# STM32H503 register map
File version: 0.3
CPU: CM33 r0p0, little endian, MPU, FPU, 4 interrupt priority bits
Registers are 32-bit, read-write, reset 0x0 unless marked. A register's access mark holds for its fields unless they carry their own. Offsets are from the block's base; [hi:lo] are bit positions.

## RCC — Reset and clock controller
Base 0x44020C00
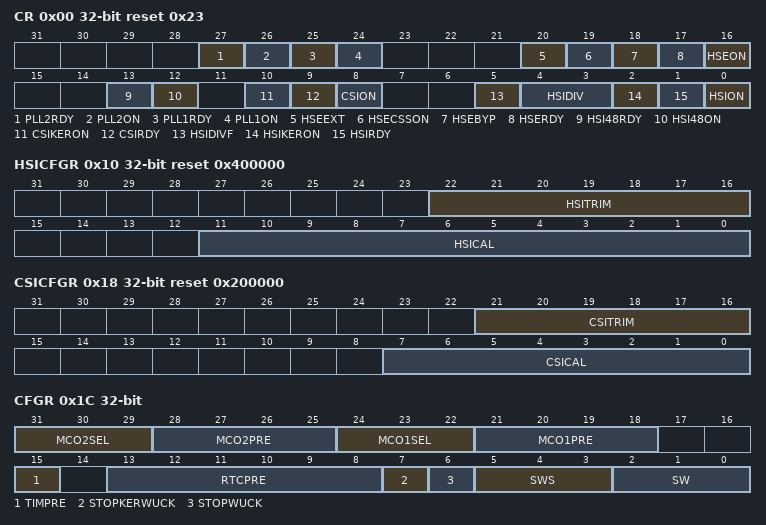
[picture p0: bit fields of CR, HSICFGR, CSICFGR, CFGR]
0x00 CR access per field reset 0x23 — RCC clock control register
  [27] PLL2RDY ro — PLL2 clock ready flag Set by hardware to indicate that the PLL is locked.
  [26] PLL2ON rw — PLL2 enable Set and cleared by software to enable PLL2. Cleared by hardware when entering Stop or Standby mode.
  [25] PLL1RDY ro — PLL1 clock ready flag Set by hardware to indicate that the PLL1 is locked.
  [24] PLL1ON rw — PLL1 enable Set and cleared by software to enable PLL1. Cleared by hardware when entering Stop or Standby mode. Note that the hardware prevents writing this bit to 0, if the PLL1 output is used as the system clock.
  [20] HSEEXT rw — external high speed clock type in Bypass mode Set and reset by software to select the external clock type (analog or digital). The external clock must be enabled with the HSEON bit to be used by the device. The HSEEXT bit can be written only if the HSE oscillator is disabled.
  [19] HSECSSON rw — HSE clock security system enable Set by software to enable clock security system on HSE. This bit is “set only” (disabled by a system reset or when the system enters in Standby mode). When HSECSSON is set, the clock detector is enabled by hardware when the HSE is ready and disabled by hardware if an oscillator failure is detected.
  [18] HSEBYP rw — HSE clock bypass Set and cleared by software to bypass the oscillator with an external clock. The external clock must be enabled with the HSEON bit to be used by the device. The HSEBYP bit can be written only if the HSE oscillator is disabled.
  [17] HSERDY ro — HSE clock ready flag Set by hardware to indicate that the HSE oscillator is stable.
  [16] HSEON rw — HSE clock enable Set and cleared by software. Cleared by hardware to stop the HSE when entering Stop or Standby mode. This bit cannot be cleared if the HSE is used directly (via SW mux) as system clock, or if the HSE is selected as reference clock for PLL1 with PLL1 enabled (PLL1ON bit set to 1).
  [13] HSI48RDY ro — HSI48 clock ready flag Set by hardware to indicate that the HSI48 oscillator is stable.
  [12] HSI48ON rw — HSI48 clock enable Set by software and cleared by software or by the hardware when the system enters to Stop or Standby mode.
  [10] CSIKERON rw — CSI clock enable in Stop mode Set and reset by software to force the CSI to ON, even in Stop mode, in order to be quickly available as kernel clock for some peripherals. This bit has no effect on the value of CSION.
  [9] CSIRDY ro — CSI clock ready flag Set by hardware to indicate that the CSI oscillator is stable. This bit is activated only if the RC is enabled by CSION (it is not activated if the CSI is enabled by CSIKERON or by a peripheral request).
  [8] CSION rw — CSI clock enable Set and reset by software to enable/disable CSI clock for system and/or peripheral. Set by hardware to force the CSI to ON when the system leaves Stop mode, if STOPWUCK = 1 or STOPKERWUCK = 1. This bit cannot be cleared if the CSI is used directly (via SW mux) as system clock, or if the CSI is selected as reference clock for PLL1 with PLL1 enabled (PLL1ON bit set to 1).
  [5] HSIDIVF ro — HSI divider flag Set and reset by hardware. As a write operation to HSIDIV has not an immediate effect on the frequency, this flag indicates the current status of the HSI divider. HSIDIVF goes immediately to 0 when HSIDIV value is changed, and is set back to 1 when the output frequency matches the value programmed into HSIDIV.
  [4:3] HSIDIV rw — HSI clock divider Set and reset by software. These bits allow selecting a division ratio in order to configure the wanted HSI clock frequency. The HSIDIV cannot be changed if the HSI is selected as reference clock for at least one enabled PLL (PLLxON bit set to 1). In that case, the new HSIDIV value is ignored.
  [2] HSIKERON rw — HSI clock enable in Stop mode Set and reset by software to force the HSI to ON, even in Stop mode, in order to be quickly available as kernel clock for peripherals. This bit has no effect on the value of HSION.
  [1] HSIRDY ro — HSI clock ready flag Set by hardware to indicate that the HSI oscillator is stable.
  [0] HSION rw — HSI clock enable Set and cleared by software. Set by hardware to force the HSI to ON when the product leaves Stop mode, if STOPWUCK = 1 or STOPKERWUCK = 1. Set by hardware to force the HSI to ON when the product leaves Standby mode or in case of a failure of the HSE which is used as the system clock source. This bit cannot be cleared if the HSI is used directly (via SW mux) as system clock, or if the HSI is selected as reference clock for PLL1 with PLL1 enabled (PLL1ON bit set to 1).
0x10 HSICFGR access per field reset 0x400000 (reset mask 0xFFFFF000) — RCC HSI calibration register
  [22:16] HSITRIM rw — HSI clock trimming Set by software to adjust calibration. HSITRIM field is added to the engineering option bytes loaded during reset phase (FLASH_HSI_OPT) in order to form the calibration trimming value. HSICAL = HSITRIM + FLASH_HSI_OPT. After a change of HSITRIM it takes one system clock cycle before the new HSITRIM value is updated Note: The reset value of the field is 0x40.
  [11:0] HSICAL ro — HSI clock calibration Set by hardware by option byte loading during system reset nreset. Adjusted by software through trimming bits HSITRIM. This field represents the sum of engineering option byte calibration value and HSITRIM bits value.
0x14 CRRCR ro (reset mask 0xFFFFF000) — RCC clock recovery RC register
  [9:0] HSI48CAL — Internal RC 48 MHz clock calibration Set by hardware by option-byte loading during system reset NRESET. Read-only.
0x18 CSICFGR reset 0x200000 (reset mask 0xFFFFF000) — RCC CSI calibration register
  [21:16] CSITRIM — CSI clock trimming Set by software to adjust calibration. CSITRIM field is added to the engineering option bytes loaded during reset phase (FLASH_CSI_OPT) in order to form the calibration trimming value. CSICAL = CSITRIM + FLASH_CSI_OPT. Note: The reset value of the field is 0x20.
  [7:0] CSICAL — CSI clock calibration Set by hardware by option byte loading during system reset NRESET. Adjusted by software through trimming bits CSITRIM. This field represents the sum of engineering option byte calibration value and CSITRIM bits value.
0x1C CFGR access per field — RCC clock configuration register
  [31:29] MCO2SEL rw — microcontroller clock output 2 Set and cleared by software. Clock source selection may generate glitches on MCO2. It is highly recommended to configure these bits only after reset, before enabling the external oscillators and the PLLs. others: reserved
  [28:25] MCO2PRE rw — MCO2 prescaler Set and cleared by software to configure the prescaler of the MCO2. Modification of this prescaler may generate glitches on MCO2. It is highly recommended to change this prescaler only after reset, before enabling the external oscillators and the PLLs. ...
  [24:22] MCO1SEL rw — Microcontroller clock output 1 Set and cleared by software. Clock source selection may generate glitches on MCO1. It is highly recommended to configure these bits only after reset, before enabling the external oscillators and the PLLs. others: reserved
  [21:18] MCO1PRE rw — MCO1 prescaler Set and cleared by software to configure the prescaler of the MCO1. Modification of this prescaler may generate glitches on MCO1. It is highly recommended to change this prescaler only after reset, before enabling the external oscillators and the PLLs. ...
  [15] TIMPRE rw — timers clocks prescaler selection This bit is set and reset by software to control the clock frequency of all the timers connected to APB1 and APB2 domains.
  [13:8] RTCPRE rw — HSE division factor for RTC clock Set and cleared by software to divide the HSE to generate a clock for RTC. Caution: The software must set these bits correctly to ensure that the clock supplied to the RTC is lower than 1 MHz. These bits must be configured if needed before selecting the RTC clock source. ...
  [7] STOPKERWUCK rw — kernel clock selection after a wakeup from system Stop Set and reset by software to select the kernel wakeup clock from system Stop.
  [6] STOPWUCK rw — system clock selection after a wakeup from system Stop Set and reset by software to select the system wakeup clock from system Stop. The selected clock is also used as emergency clock for the clock security system (CSS) on HSE. 0: HSI selected as wakeup clock from system Stop (default after reset) STOPWUCK must not be modified when CSS is enabled (by HSECSSON bit) and the system clock is HSE (SWS = 10) or a switch on HSE is requested (SW =10).
  [5:3] SWS ro — system clock switch status Set and reset by hardware to indicate which clock source is used as system clock. 000: HSI used as system clock (hsi_ck) (default after reset). others: reserved
  [2:0] SW rw — system clock and trace clock switch Set and reset by software to select system clock and trace clock sources (sys_ck). Set by hardware in order to: - force the selection of the HSI or CSI (depending on STOPWUCK selection) when leaving a system Stop mode - force the selection of the HSI in case of failure of the HSE when used directly or indirectly as system clock others: reserved
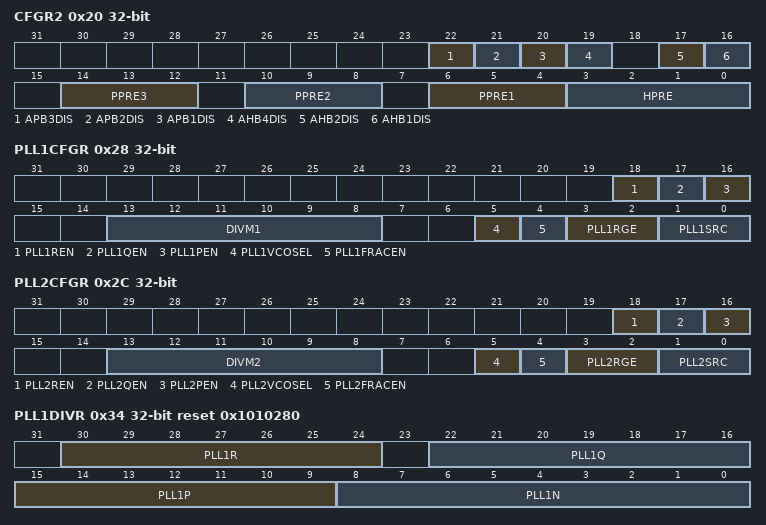
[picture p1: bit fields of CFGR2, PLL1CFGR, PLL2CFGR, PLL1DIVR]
0x20 CFGR2 — RCC CPU domain clock configuration register 2
  [22] APB3DIS — APB3 clock disable value.Set and cleared by software This bit can be set in order to further reduce power consumption, when none of the APB3 peripherals are used and when their clocks are disabled in RCC_APB3ENR. When this bit is set, all the APB3 peripherals clocks are off. control bits
  [21] APB2DIS — APB2 clock disable value This bit can be set in order to further reduce power consumption, when none of the APB2 peripherals are used and when their clocks are disabled in RCC_APB2ENR. When this bit is set, all the APB2 peripherals clocks are off. control bits
  [20] APB1DIS — APB1 clock disable value This bit can be set in order to further reduce power consumption, when none of the APB1 peripherals (except IWDG) are used and when their clocks are disabled in RCC_APB1ENR. When this bit is set, all the APB1 peripherals clocks are off, except for IWDG. control bits
  [19] AHB4DIS — AHB4 clock disable This bit can be set in order to further reduce power consumption, when none of the AHB4 peripherals from RCC_AHB4ENR are used and when their clocks are disabled in RCC_AHB4ENR. When this bit is set, all the AHB4 peripherals clocks from RCC_AHB4ENR are off. enable control bits
  [17] AHB2DIS — AHB2 clock disable This bit can be set in order to further reduce power consumption, when none of the AHB2 peripherals from RCC_AHB2ENR are used and when their clocks are disabled in RCC_AHB2ENR. When this bit is set, all the AHB2 peripherals clocks from RCC_AHB2ENR are off. enable control bits
  [16] AHB1DIS — AHB1 clock disable This bit can be set in order to further reduce power consumption, when none of the AHB1 peripherals from RCC_AHB1ENR are used and when their clocks are disabled in RCC_AHB1ENR. When this bit is set, all the AHB1 peripherals clocks from RCC_AHB1ENR are off. enable control bits
  [14:12] PPRE3 — APB low-speed prescaler (APB3) Set and reset by software to control APB low-speed clocks division factor. The clocks are divided with the new prescaler factor from 1 to 16 APB cycles after PPRE3 write. 0xx: rcc_pclk3 = rcc_hclk1
  [10:8] PPRE2 — APB high-speed prescaler (APB2) Set and reset by software to control APB high-speed clocks division factor. The clocks are divided with the new prescaler factor from 1 to 16 APB cycles after PPRE2 write. 0xx: rcc_pclk2 = rcc_hclk1
  [6:4] PPRE1 — APB low-speed prescaler (APB1) Set and reset by software to control the division factor of rcc_pclk1. The clock is divided by the new prescaler factor from 1 to 16 cycles of rcc_hclk after PPRE write. 0xx: rcc_pclk1 = rcc_hclk1 (default after reset)
  [3:0] HPRE — AHB prescaler Set and reset by software to control the division factor of rcc_hclk. Changing this division ratio has an impact on the frequency of all bus matrix clocks 0xxx: rcc_hclk = sys_ck (default after reset)
0x28 PLL1CFGR — RCC PLL clock source selection register
  [18] PLL1REN — PLL1 DIVR divider output enable Set and reset by software to enable the pll1_r_ck output of the PLL1. To save power, DIVR1EN and DIVR1 bits must be set to 0 when the pll1_r_ck is not used. This bit can be written only when the PLL1 is disabled (PLL1ON = 0 and PLL1RDY = 0).
  [17] PLL1QEN — PLL1 DIVQ divider output enable Set and reset by software to enable the pll1_q_ck output of the PLL1. In order to save power, when the pll1_q_ck output of the PLL1 is not used, the pll1_q_ck must be disabled. This bit can be written only when the PLL1 is disabled (PLL1ON = 0 and PLL1RDY = 0).
  [16] PLL1PEN — PLL1 DIVP divider output enable Set and reset by software to enable the pll1_p_ck output of the PLL1. This bit can be written only when the PLL1 is disabled (PLL1ON = 0 and PLL1RDY = 0). In order to save power, when the pll1_p_ck output of the PLL1 is not used, the pll1_p_ck must be disabled.
  [13:8] DIVM1 — prescaler for PLL1 Set and cleared by software to configure the prescaler of the PLL1. The hardware does not allow any modification of this prescaler when PLL1 is enabled (PLL1ON = 1 or PLL1RDY = 1). In order to save power when PLL1 is not used, the value of DIVM1 must be set to 0. ... ...
  [5] PLL1VCOSEL — PLL1 VCO selection Set and reset by software to select the proper VCO frequency range used for PLL1. This bit must be written before enabling the PLL1.
  [4] PLL1FRACEN — PLL1 fractional latch enable Set and reset by software to latch the content of FRACN1 into the sigma-delta modulator. In order to latch the FRACN1 value into the sigma-delta modulator, PLL1FRACEN must be set to 0, then set to 1. The transition 0 to 1 transfers the content of FRACN1 into the modulator.
  [3:2] PLL1RGE — PLL1 input frequency range Set and reset by software to select the proper reference frequency range used for PLL1. This bit must be written before enabling the PLL1.
  [1:0] PLL1SRC — DIVMx and PLLs clock source selection Set and reset by software to select the PLL clock source. These bits can be written only when all PLLs are disabled. In order to save power, when no PLL is used, the value of PLL1SRC must be set to '00'. 00: no clock send to DIVMx divider and PLLs (default after reset).
0x2C PLL2CFGR — RCC PLL clock source selection register
  [18] PLL2REN — PLL2 DIVR divider output enable Set and reset by software to enable the pll2_r_ck output of the PLL2. To save power, DIVR2EN and DIVR2 bits must be set to 0 when the pll2_r_ck is not used.
  [17] PLL2QEN — PLL2 DIVQ divider output enable Set and reset by software to enable the pll2_q_ck output of the PLL2. To save power, when the pll2_q_ck output of the PLL2 is not used, the pll2_q_ck must be disabled.
  [16] PLL2PEN — PLL2 DIVP divider output enable Set and reset by software to enable the pll2_p_ck output of the PLL2. To save power, when the pll2_p_ck output of the PLL2 is not used, the pll2_p_ck must be disabled.
  [13:8] DIVM2 — prescaler for PLL2 Set and cleared by software to configure the prescaler of the PLL2. The hardware does not allow any modification of this prescaler when PLL2 is enabled (PLL2ON = 1 or PLL2RDY = 1). In order to save power when PLL2 is not used, the value of DIVM2 must be set to 0. ... ...
  [5] PLL2VCOSEL — PLL2 VCO selection Set and reset by software to select the proper VCO frequency range used for PLL2. This bit must be written before enabling the PLL2.
  [4] PLL2FRACEN — PLL2 fractional latch enable Set and reset by software to enable the pll2_p_ck output of the PLL2. To save power, when the pll2_p_ck output of the PLL2 is not used, the pll2_p_ck must be disabled.
  [3:2] PLL2RGE — PLL2 input frequency range Set and reset by software to select the proper reference frequency range used for PLL2. These bits must be written before enabling the PLL2.
  [1:0] PLL2SRC — DIVMx and PLLs clock source selection Set and reset by software to select the PLL clock source. These bits can be written only when all PLLs are disabled. In order to save power, when no PLL is used, the value of PLL2SRC must be set to '00'.
0x34 PLL1DIVR reset 0x1010280 — RCC PLL1 dividers register
  [30:24] PLL1R — PLL1 DIVR division factor Set and reset by software to control the frequency of the pll1_r_ck clock. These bits can be written only when the PLL1 is disabled (PLL1ON = 0 and PLL1RDY = 0). ...
  [22:16] PLL1Q — PLL1 DIVQ division factor Set and reset by software to control the frequency of the pll1_q_ck clock. These bits can be written only when the PLL1 is disabled (PLL1ON = 0 and PLL1RDY = 0). ...
  [15:9] PLL1P — PLL1 DIVP division factor Set and reset by software to control the frequency of the pll1_p_ck clock. These bits can be written only when the PLL1 is disabled (PLL1ON = 0 and PLL1RDY = 0). Note that odd division factors are not allowed. ...
  [8:0] PLL1N — Multiplication factor for PLL1VCO Set and reset by software to control the multiplication factor of the VCO. These bits can be written only when the PLL is disabled (PLL1ON = 0 and PLL1RDY = 0). ... ... Others: reserved
0x38 PLL1FRACR — RCC PLL1 fractional divider register
  [15:3] PLL1FRACN — fractional part of the multiplication factor for PLL1 VCO Set and reset by software to control the fractional part of the multiplication factor of the VCO. These bits can be written at any time, allowing dynamic fine-tuning of the PLL1 VCO. The software must set correctly these bits to insure that the VCO output frequency is between its valid frequency range, that is: * 128 to 560 MHz if PLL1VCOSEL = 0 * 150 to 420 MHz if PLL1VCOSEL = 1 VCO output frequency = Fref1_ck x (PLL1N + (PLL1FRACN / 213)), with * PLL1N between 8 and 420 * PLL1FRACN can be between 0 and 213- 1 * The input frequency Fref1_ck must be between 1 and 16 MHz. To change the PLL1FRACN value on-the-fly even if the PLL is enabled, the application must proceed as follows: * Set the bit PLL1FRACEN to 0 * Write the new fractional value into PLL1FRACN * Set the bit PLL1FRACEN to 1
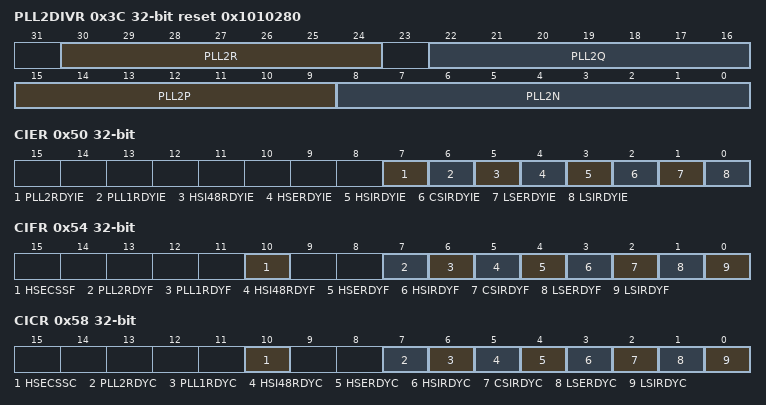
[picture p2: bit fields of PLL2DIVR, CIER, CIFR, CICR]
0x3C PLL2DIVR reset 0x1010280 — RCC PLL1 dividers register
  [30:24] PLL2R — PLL2 DIVR division factor Set and reset by software to control the frequency of the pll2_r_ck clock. These bits can be written only when the PLL1 is disabled (PLL2ON = 0 and PLL2RDY = 0). ...
  [22:16] PLL2Q — PLL2 DIVQ division factor Set and reset by software to control the frequency of the pll2_q_ck clock. These bits can be written only when the PLL2 is disabled (PLL2ON = 0 and PLL2RDY = 0). ...
  [15:9] PLL2P — PLL2 DIVP division factor Set and reset by software to control the frequency of the pll2_p_ck clock. These bits can be written only when the PLL2 is disabled (PLL2ON = 0 and PLL2RDY = 0). ...
  [8:0] PLL2N — Multiplication factor for PLL2VCO Set and reset by software to control the multiplication factor of the VCO. These bits can be written only when the PLL is disabled (PLL2ON = 0 and PLL2RDY = 0). ... ... Others: reserved
0x40 PLL2FRACR — RCC PLL2 fractional divider register
  [15:3] PLL2FRACN — fractional part of the multiplication factor for PLL2 VCO Set and reset by software to control the fractional part of the multiplication factor of the VCO. These bits can be written at any time, allowing dynamic fine-tuning of the PLL2 VCO. The software must set correctly these bits to insure that the VCO output frequency is between its valid frequency range, that is: * 128 to 560 MHz if PLL2VCOSEL = 0 * 150 to 420 MHz if PLL2VCOSEL = 1 VCO output frequency = Fref2_ck x (PLL2N + (PLL2FRACN / 213)), with * PLL2N between 8 and 420 * PLL2FRACN can be between 0 and 213- 1 * The input frequency Fref2_ck must be between 1 and 16 MHz. To change the PLL2FRACN value on-the-fly even if the PLL is enabled, the application must proceed as follows: * Set the bit PLL2FRACEN to 0 * Write the new fractional value into PLL2FRACN * Set the bit PLL2FRACEN to 1
0x50 CIER — RCC clock source interrupt enable register
  [7] PLL2RDYIE — PLL2 ready interrupt enable Set and reset by software to enable/disable interrupt caused by PLL2 lock.
  [6] PLL1RDYIE — PLL1 ready interrupt enable Set and reset by software to enable/disable interrupt caused by PLL1 lock.
  [5] HSI48RDYIE — HSI48 ready interrupt enable Set and reset by software to enable/disable interrupt caused by the HSI48 oscillator stabilization.
  [4] HSERDYIE — HSE ready interrupt enable Set and reset by software to enable/disable interrupt caused by the HSE oscillator stabilization.
  [3] HSIRDYIE — HSI ready interrupt enable Set and reset by software to enable/disable interrupt caused by the HSI oscillator stabilization.
  [2] CSIRDYIE — CSI ready interrupt enable Set and reset by software to enable/disable interrupt caused by the CSI oscillator stabilization.
  [1] LSERDYIE — LSE ready interrupt enable Set and reset by software to enable/disable interrupt caused by the LSE oscillator stabilization.
  [0] LSIRDYIE — LSI ready interrupt enable Set and reset by software to enable/disable interrupt caused by the LSI oscillator stabilization.
0x54 CIFR ro — RCC clock source interrupt flag register
  [10] HSECSSF — HSE clock security system interrupt flag Reset by software by writing HSECSSC bit. Set by hardware in case of HSE clock failure.
  [7] PLL2RDYF — PLL2 ready interrupt flag Reset by software by writing PLL2RDYC bit. Set by hardware when the PLL2 locks and PLL2RDYIE is set.
  [6] PLL1RDYF — PLL1 ready interrupt flag Reset by software by writing PLL1RDYC bit. Set by hardware when the PLL1 locks and PLL1RDYIE is set.
  [5] HSI48RDYF — HSI48 ready interrupt flag Reset by software by writing HSI48RDYC bit. Set by hardware when the HSI48 clock becomes stable and HSI48RDYIE is set.
  [4] HSERDYF — HSE ready interrupt flag Reset by software by writing HSERDYC bit. Set by hardware when the HSE clock becomes stable and HSERDYIE is set.
  [3] HSIRDYF — HSI ready interrupt flag Reset by software by writing HSIRDYC bit. Set by hardware when the HSI clock becomes stable and HSIRDYIE is set.
  [2] CSIRDYF — CSI ready interrupt flag Reset by software by writing CSIRDYC bit. Set by hardware when the CSI clock becomes stable and CSIRDYIE is set.
  [1] LSERDYF — LSE ready interrupt flag Reset by software by writing LSERDYC bit. Set by hardware when the LSE clock becomes stable and LSERDYIE is set.
  [0] LSIRDYF — LSI ready interrupt flag Reset by software by writing LSIRDYC bit. Set by hardware when the LSI clock becomes stable and LSIRDYIE is set.
0x58 CICR — RCC clock source interrupt clear register
  [10] HSECSSC — HSE clock security system interrupt clear Set by software to clear HSECSSF. Reset by hardware when clear done.
  [7] PLL2RDYC — PLL2 ready interrupt clear Set by software to clear PLL2RDYF. Reset by hardware when clear done.
  [6] PLL1RDYC — PLL1 ready interrupt clear Set by software to clear PLL1RDYF. Reset by hardware when clear done.
  [5] HSI48RDYC — HSI48 ready interrupt clear Set by software to clear HSI48RDYF. Reset by hardware when clear done.
  [4] HSERDYC — HSE ready interrupt clear Set by software to clear HSERDYF. Reset by hardware when clear done.
  [3] HSIRDYC — HSI ready interrupt clear Set by software to clear HSIRDYF. Reset by hardware when clear done.
  [2] CSIRDYC — HSI ready interrupt clear Set by software to clear CSIRDYF. Reset by hardware when clear done.
  [1] LSERDYC — LSE ready interrupt clear Set by software to clear LSERDYF. Reset by hardware when clear done.
  [0] LSIRDYC — LSI ready interrupt clear Set by software to clear LSIRDYF. Reset by hardware when clear done.
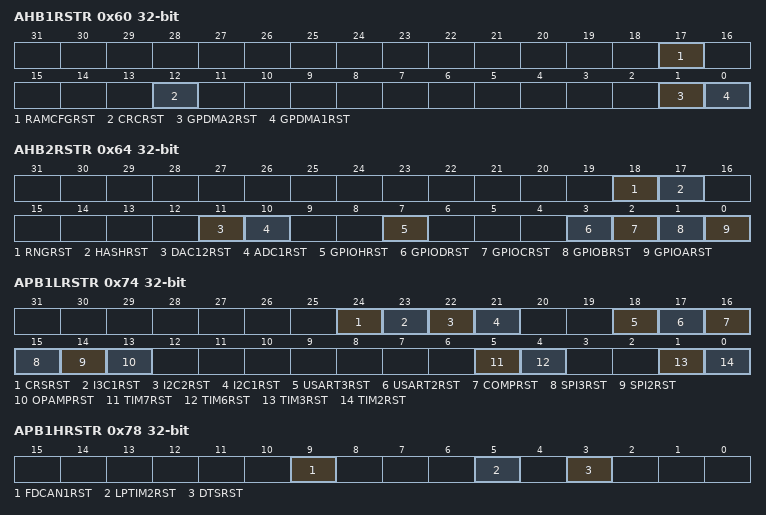
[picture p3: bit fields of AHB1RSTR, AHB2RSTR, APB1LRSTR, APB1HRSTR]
0x60 AHB1RSTR — RCC AHB1 reset register
  [17] RAMCFGRST — RAMCFG block reset Set and reset by software.
  [12] CRCRST — CRC block reset Set and reset by software.
  [1] GPDMA2RST — GPDMA2 block reset Set and reset by software.
  [0] GPDMA1RST — GPDMA1 block reset Set and reset by software.
0x64 AHB2RSTR — RCC AHB2 peripheral reset register
  [18] RNGRST — RNG block reset Set and reset by software.
  [17] HASHRST — HASH block reset Set and reset by software.
  [11] DAC12RST — DAC block reset Set and reset by software.
  [10] ADC1RST — ADC1 block reset Set and reset by software.
  [7] GPIOHRST — GPIOH block reset Set and reset by software.
  [3] GPIODRST — GPIOD block reset Set and reset by software.
  [2] GPIOCRST — GPIOC block reset Set and reset by software.
  [1] GPIOBRST — GPIOB block reset Set and reset by software.
  [0] GPIOARST — GPIOA block reset Set and reset by software.
0x74 APB1LRSTR — RCC APB1 peripheral low reset register
  [24] CRSRST — CRS block reset Set and reset by software.
  [23] I3C1RST — I3C1 block reset Set and reset by software.
  [22] I2C2RST — I2C2 block reset Set and reset by software.
  [21] I2C1RST — I2C1 block reset Set and reset by software.
  [18] USART3RST — USART3 block reset Set and reset by software.
  [17] USART2RST — USART2 block reset Set and reset by software.
  [16] COMPRST — COMP block reset Set and reset by software.
  [15] SPI3RST — SPI3 block reset Set and reset by software.
  [14] SPI2RST — SPI2 block reset Set and reset by software.
  [13] OPAMPRST — OPAMP block reset Set and reset by software.
  [5] TIM7RST — TIM7 block reset Set and reset by software.
  [4] TIM6RST — TIM6 block reset Set and reset by software.
  [1] TIM3RST — TIM3 block reset Set and reset by software.
  [0] TIM2RST — TIM2 block reset Set and reset by software.
0x78 APB1HRSTR — RCC APB1 peripheral high reset register
  [9] FDCAN1RST — FDCAN1 block reset Set and reset by software.
  [5] LPTIM2RST — LPTIM2 block reset Set and reset by software.
  [3] DTSRST — DTS block reset Set and reset by software.
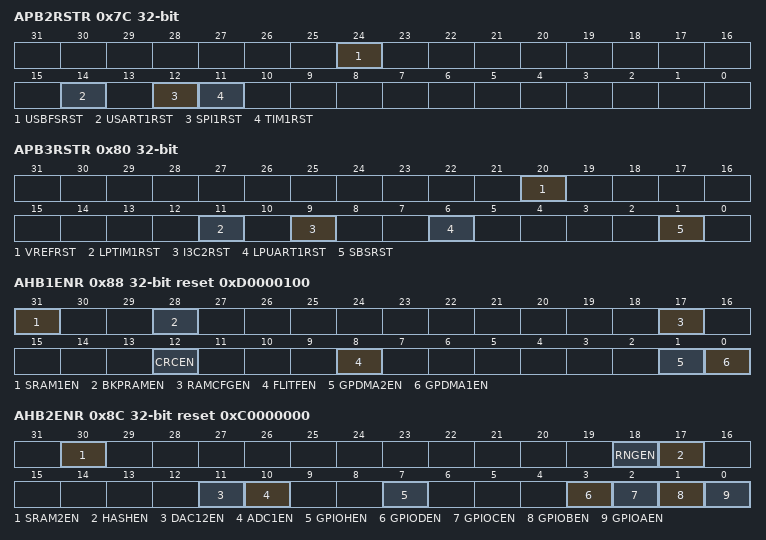
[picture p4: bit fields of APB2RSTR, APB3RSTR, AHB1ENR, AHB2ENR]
0x7C APB2RSTR — RCC APB2 peripheral reset register
  [24] USBFSRST — USBFS block reset Set and reset by software.
  [14] USART1RST — USART1 block reset Set and reset by software.
  [12] SPI1RST — SPI1 block reset Set and reset by software.
  [11] TIM1RST — TIM1 block reset Set and reset by software.
0x80 APB3RSTR — RCC APB3 peripheral reset register
  [20] VREFRST — VREF block reset Set and reset by software.
  [11] LPTIM1RST — LPTIM1 block reset Set and reset by software.
  [9] I3C2RST — I3C2RST block reset Set and reset by software.
  [6] LPUART1RST — LPUART1 block reset Set and reset by software.
  [1] SBSRST — SBS block reset Set and reset by software.
0x88 AHB1ENR reset 0xD0000100 — RCC AHB1 peripherals clock register
  [31] SRAM1EN — SRAM1 clock enable Set and reset by software.
  [28] BKPRAMEN — BKPRAM clock enable Set and reset by software
  [17] RAMCFGEN — RAMCFG clock enable Set and reset by software.
  [12] CRCEN — CRC clock enable Set and reset by software.
  [8] FLITFEN — Flash interface clock enable Set and reset by software.
  [1] GPDMA2EN — GPDMA2 clock enable Set and reset by software.
  [0] GPDMA1EN — GPDMA1 clock enable Set and reset by software.
0x8C AHB2ENR reset 0xC0000000 — RCC AHB2 peripheral clock register
  [30] SRAM2EN — SRAM2 clock enable Set and reset by software.
  [18] RNGEN — RNG clock enable Set and reset by software.
  [17] HASHEN — HASH clock enable Set and reset by software.
  [11] DAC12EN — DAC clock enable Set and reset by software.
  [10] ADC1EN — ADC1 peripherals clock enabled Set and reset by software.
  [7] GPIOHEN — GPIOH clock enable Set and reset by software.
  [3] GPIODEN — GPIOD clock enable Set and reset by software.
  [2] GPIOCEN — GPIOC clock enable Set and reset by software.
  [1] GPIOBEN — GPIOB clock enable Set and reset by software.
  [0] GPIOAEN — GPIOA clock enable Set and reset by software.
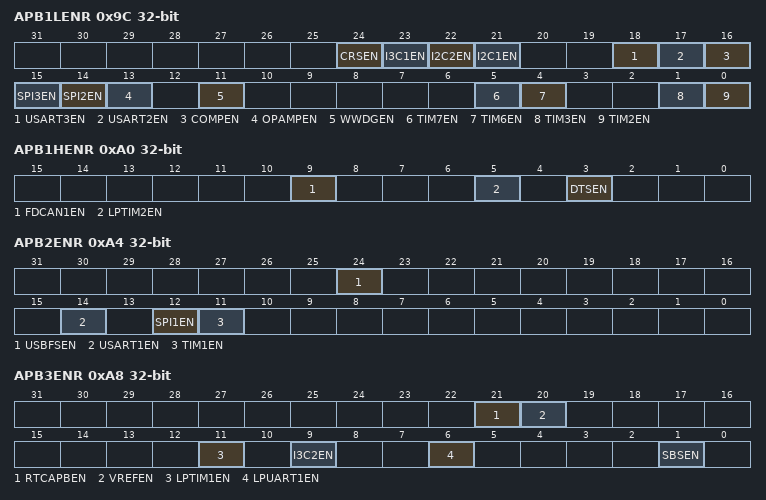
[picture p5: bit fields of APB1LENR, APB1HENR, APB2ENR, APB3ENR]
0x9C APB1LENR — RCC APB1 peripheral clock register
  [24] CRSEN — CRS clock enable Set and reset by software.
  [23] I3C1EN — I3C1 clock enable Set and reset by software.
  [22] I2C2EN — I2C2 clock enable Set and reset by software.
  [21] I2C1EN — I2C1 clock enable Set and reset by software.
  [18] USART3EN — USART3 clock enable Set and reset by software.
  [17] USART2EN — USART2 clock enable Set and reset by software.
  [16] COMPEN — COMP clock enable Set and reset by software.
  [15] SPI3EN — SPI3 clock enable Set and reset by software.
  [14] SPI2EN — SPI2 clock enable Set and reset by software.
  [13] OPAMPEN — OPAMP clock enable Set and reset by software.
  [11] WWDGEN — WWDG clock enable Set and reset by software.
  [5] TIM7EN — TIM7 clock enable Set and reset by software.
  [4] TIM6EN — TIM6 clock enable Set and reset by software.
  [1] TIM3EN — TIM3 clock enable Set and reset by software.
  [0] TIM2EN — TIM2 clock enable Set and reset by software.
0xA0 APB1HENR — RCC APB1 peripheral clock register
  [9] FDCAN1EN — FDCAN1 peripheral clock enable Set and reset by software.
  [5] LPTIM2EN — LPTIM2 clock enable Set and reset by software.
  [3] DTSEN — DTS clock enable Set and reset by software.
0xA4 APB2ENR — RCC APB2 peripheral clock register
  [24] USBFSEN — USBFS clock enable Set and reset by software.
  [14] USART1EN — USART1 clock enable Set and reset by software.
  [12] SPI1EN — SPI1 clock enable Set and reset by software.
  [11] TIM1EN — TIM1 clock enable Set and reset by software.
0xA8 APB3ENR — RCC APB3 peripheral clock register
  [21] RTCAPBEN — RTC APB interface clock enable Set and reset by software.
  [20] VREFEN — VREF clock enable Set and reset by software.
  [11] LPTIM1EN — LPTIM1 clock enable Set and reset by software.
  [9] I3C2EN — I3C2EN clock enable Set and reset by software.
  [6] LPUART1EN — LPUART1 clock enable Set and reset by software.
  [1] SBSEN — SBS clock enable Set and reset by software.
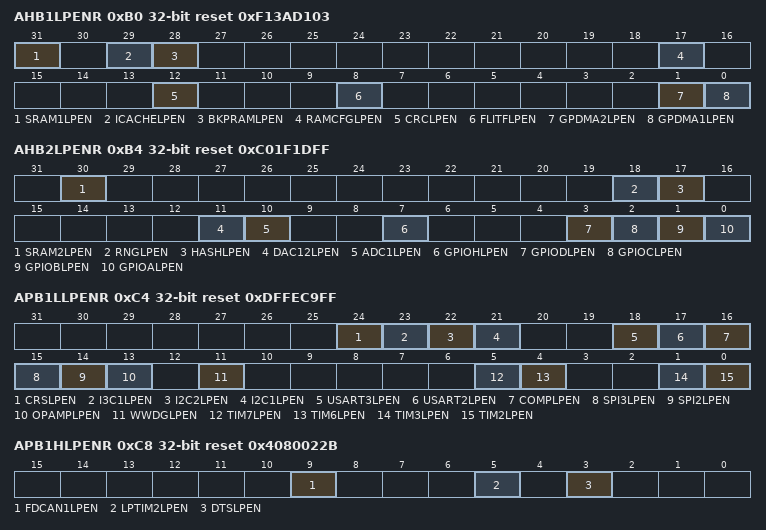
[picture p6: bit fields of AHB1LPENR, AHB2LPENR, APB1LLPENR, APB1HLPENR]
0xB0 AHB1LPENR reset 0xF13AD103 — RCC AHB1 sleep clock register
  [31] SRAM1LPEN — SRAM1 clock enable during sleep mode Set and reset by software
  [29] ICACHELPEN — ICACHE clock enable during sleep mode Set and reset by software
  [28] BKPRAMLPEN — BKPRAM clock enable during sleep mode Set and reset by software
  [17] RAMCFGLPEN — RAMCFG clock enable during sleep mode Set and reset by software.
  [12] CRCLPEN — CRC clock enable during sleep mode Set and reset by software.
  [8] FLITFLPEN — Flash interface (FLITF) clock enable during sleep mode Set and reset by software.
  [1] GPDMA2LPEN — GPDMA2 clock enable during sleep mode Set and reset by software.
  [0] GPDMA1LPEN — GPDMA1 clock enable during sleep mode Set and reset by software.
0xB4 AHB2LPENR reset 0xC01F1DFF — RCC AHB2 sleep clock register
  [30] SRAM2LPEN — SRAM2 clock enable during sleep mode Set and reset by software.
  [18] RNGLPEN — RNG clock enable during sleep mode Set and reset by software.
  [17] HASHLPEN — HASH clock enable during sleep mode Set and reset by software.
  [11] DAC12LPEN — DAC clock enable during sleep mode Set and reset by software.
  [10] ADC1LPEN — ADC1 peripherals clock enable during sleep mode Set and reset by software.
  [7] GPIOHLPEN — GPIOH clock enable during sleep mode Set and reset by software.
  [3] GPIODLPEN — GPIOD clock enable during sleep mode Set and reset by software.
  [2] GPIOCLPEN — GPIOC clock enable during sleep mode Set and reset by software.
  [1] GPIOBLPEN — GPIOB clock enable during sleep mode Set and reset by software.
  [0] GPIOALPEN — GPIOA clock enable during sleep mode Set and reset by software.
0xC4 APB1LLPENR reset 0xDFFEC9FF — RCC APB1 sleep clock register
  [24] CRSLPEN — CRS clock enable during sleep mode Set and reset by software.
  [23] I3C1LPEN — I3C1 clock enable during sleep mode Set and reset by software.
  [22] I2C2LPEN — I2C2 clock enable during sleep mode Set and reset by software.
  [21] I2C1LPEN — I2C1 clock enable during sleep mode Set and reset by software.
  [18] USART3LPEN — USART3 clock enable during sleep mode Set and reset by software.
  [17] USART2LPEN — USART2 clock enable during sleep mode Set and reset by software.
  [16] COMPLPEN — COMP clock enable during sleep mode Set and reset by software.
  [15] SPI3LPEN — SPI3 clock enable during sleep mode Set and reset by software.
  [14] SPI2LPEN — SPI2 clock enable during sleep mode Set and reset by software.
  [13] OPAMPLPEN — OPAMP clock enable during sleep mode Set and reset by software.
  [11] WWDGLPEN — WWDG clock enable during sleep mode Set and reset by software.
  [5] TIM7LPEN — TIM7 clock enable during sleep mode Set and reset by software.
  [4] TIM6LPEN — TIM6 clock enable during sleep mode Set and reset by software.
  [1] TIM3LPEN — TIM3 clock enable during sleep mode Set and reset by software.
  [0] TIM2LPEN — TIM2 clock enable during sleep mode Set and reset by software.
0xC8 APB1HLPENR reset 0x4080022B — RCC APB1 sleep clock register
  [9] FDCAN1LPEN — FDCAN1 peripheral clock enable during sleep mode Set and reset by software.
  [5] LPTIM2LPEN — LPTIM2 clock enable during sleep mode Set and reset by software.
  [3] DTSLPEN — DTS clock enable during sleep mode Set and reset by software.
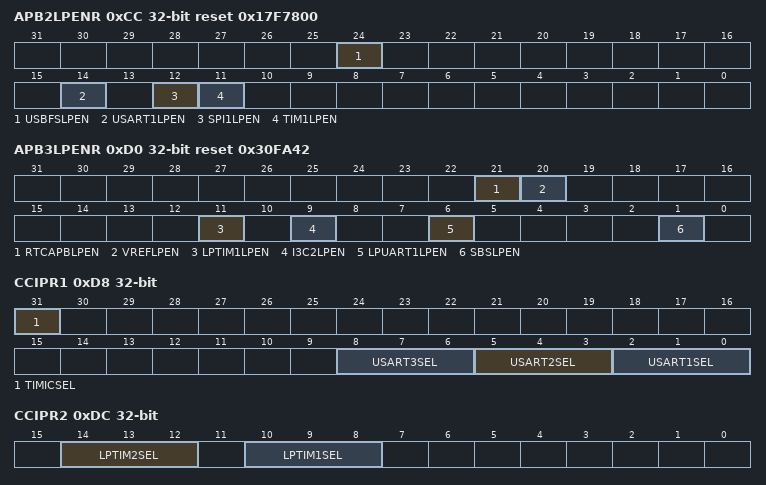
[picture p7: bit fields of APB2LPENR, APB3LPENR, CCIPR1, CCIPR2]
0xCC APB2LPENR reset 0x17F7800 — RCC APB2 sleep clock register
  [24] USBFSLPEN — USBFS clock enable during sleep mode Set and reset by software.
  [14] USART1LPEN — USART1 clock enable during sleep mode Set and reset by software.
  [12] SPI1LPEN — SPI1 clock enable during sleep mode Set and reset by software.
  [11] TIM1LPEN — TIM1 clock enable during sleep mode Set and reset by software.
0xD0 APB3LPENR reset 0x30FA42 — RCC APB3 sleep clock register
  [21] RTCAPBLPEN — RTC APB interface clock enable during sleep mode Set and reset by software.
  [20] VREFLPEN — VREF clock enable during sleep mode Set and reset by software.
  [11] LPTIM1LPEN — LPTIM1 clock enable during sleep mode Set and reset by software.
  [9] I3C2LPEN — I3C2 clock enable during sleep mode Set and reset by software.
  [6] LPUART1LPEN — LPUART1 clock enable during sleep mode Set and reset by software.
  [1] SBSLPEN — SBS clock enable during sleep mode Set and reset by software.
0xD8 CCIPR1 — RCC kernel clock configuration register
  [31] TIMICSEL — TIM2, TIM3 and LPTIM2 input capture source selection Set and reset by software.
  [8:6] USART3SEL — USART3 kernel clock source selection Set and reset by software. others: reserved, the kernel clock is disabled
  [5:3] USART2SEL — USART2 kernel clock source selection Set and reset by software. others: reserved, the kernel clock is disabled
  [2:0] USART1SEL — USART1 kernel clock source selection Set and reset by software. others: reserved, the kernel clock is disabled
0xDC CCIPR2 — RCC kernel clock configuration register
  [14:12] LPTIM2SEL — LPTIM2 kernel clock source selection others: reserved, the kernel clock is disabled
  [10:8] LPTIM1SEL — LPTIM1 kernel clock source selection others: reserved, the kernel clock is disabled
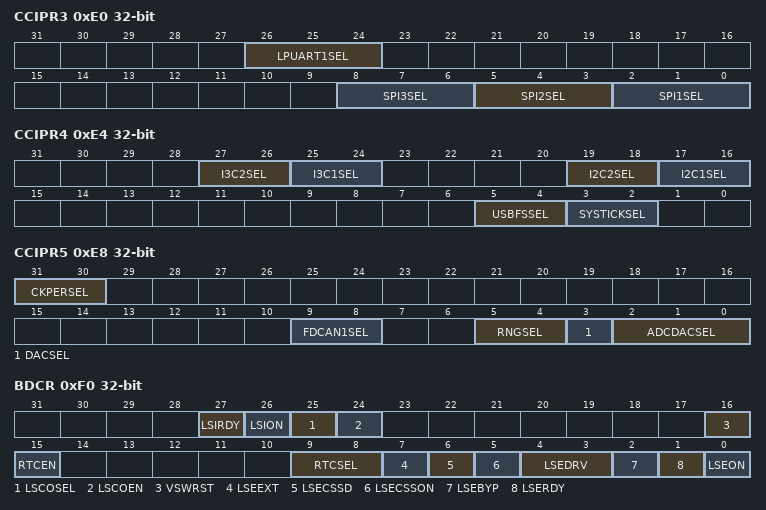
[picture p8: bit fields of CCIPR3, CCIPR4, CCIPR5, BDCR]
0xE0 CCIPR3 — RCC kernel clock configuration register
  [26:24] LPUART1SEL — LPUART1 kernel clock source selection others: reserved, the kernel clock is disabled
  [8:6] SPI3SEL — SPI3 kernel clock source selection Set and reset by software. others: reserved, the kernel clock is disabled
  [5:3] SPI2SEL — SPI2 kernel clock source selection Set and reset by software. others: reserved, the kernel clock is disabled
  [2:0] SPI1SEL — SPI1 kernel clock source selection Set and reset by software. others: reserved, the kernel clock is disabled
0xE4 CCIPR4 — RCC kernel clock configuration register
  [27:26] I3C2SEL — I3C2 kernel clock source selection
  [25:24] I3C1SEL — I3C1 kernel clock source selection
  [19:18] I2C2SEL — I2C2 kernel clock source selection
  [17:16] I2C1SEL — I2C1 kernel clock source selection
  [5:4] USBFSSEL — USBFS kernel clock source selection
  [3:2] SYSTICKSEL — SYSTICK clock source selection Note: rcc_hclk frequency must be four times higher than lsi_ker_ck/lse_ck (period (LSI/LSE) ≥ 4 * period (HCLK).
0xE8 CCIPR5 — RCC kernel clock configuration register
  [31:30] CKPERSEL — per_ck clock source selection
  [9:8] FDCAN1SEL — FDCAN1 kernel clock source selection
  [5:4] RNGSEL — RNG kernel clock source selection
  [3] DACSEL — DAC hold clock
  [2:0] ADCDACSEL — ADC and DAC kernel clock source selection others: reserved, the kernel clock is disabled
0xF0 BDCR — RCC Backup domain control register
  [27] LSIRDY — LSI oscillator ready Set and cleared by hardware to indicate when the LSI oscillator is stable. After the LSION bit is cleared, LSIRDY goes low after three internal low-speed oscillator clock cycles. This bit is set when the LSI is used by IWDG or RTC, even if LSION = 0.
  [26] LSION — LSI oscillator enable Set and cleared by software.
  [25] LSCOSEL — Low-speed clock output selection Set and cleared by software.
  [24] LSCOEN — Low-speed clock output (LSCO) enable Set and cleared by software.
  [16] VSWRST — VSwitch domain software reset Set and reset by software.
  [15] RTCEN — RTC clock enable Set and reset by software.
  [9:8] RTCSEL — RTC clock source selection Set by software to select the clock source for the RTC. These bits can be written only one time (except in case of failure detection on LSE). These bits must be written before LSECSSON is enabled. The VSWRST bit can be used to reset them, then it can be written one time again. If HSE is selected as RTC clock, this clock is lost when the system is in Stop mode or in case of a pin reset (NRST).
  [7] LSEEXT — low-speed external clock type in bypass mode Set and reset by software to select the external clock type (analog or digital). The external clock must be enabled with the LSEON bit, to be used by the device. The LSEEXT bit can be written only if the LSE oscillator is disabled.
  [6] LSECSSD — LSE clock security system failure detection Set by hardware to indicate when a failure has been detected by the clock security system on the external 32 kHz oscillator.
  [5] LSECSSON — LSE clock security system enable Set by software to enable the clock security system on 32 kHz oscillator. LSECSSON must be enabled after LSE is enabled (LSEON enabled) and ready (LSERDY set by hardware) and after RTCSEL is selected. Once enabled, this bit cannot be disabled, except after a LSE failure detection (LSECSSD = 1). In that case the software must disable LSECSSON.
  [4:3] LSEDRV — LSE oscillator driving capability Set by software to select the driving capability of the LSE oscillator. These bit can be written only if LSE oscillator is disabled (LSEON = 0 and LSERDY = 0).
  [2] LSEBYP — LSE oscillator bypass Set and reset by software to bypass oscillator in debug mode. This bit must not be written when the LSE is enabled (by LSEON) or ready (LSERDY = 1)
  [1] LSERDY — LSE oscillator ready Set and reset by hardware to indicate when the LSE is stable. This bit needs 6 cycles of lse_ck clock to fall down after LSEON has been set to 0.
  [0] LSEON — LSE oscillator enabled Set and reset by software.
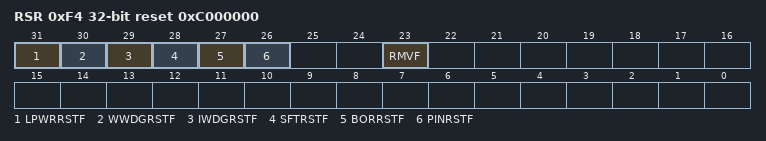
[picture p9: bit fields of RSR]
0xF4 RSR reset 0xC000000 — RCC reset status register
  [31] LPWRRSTF — Low-power reset flag Set by hardware when a reset occurs due to Stop or Standby mode entry, whereas the corresponding nRST_STOP, nRST_STBY option bit is cleared. Cleared by writing to the RMVF bit.
  [30] WWDGRSTF — window watchdog reset flag Reset by software by writing the RMVF bit. Set by hardware when a window watchdog reset occurs.
  [29] IWDGRSTF — independent watchdog reset flag Reset by software by writing the RMVF bit. Set by hardware when an independent watchdog reset occurs.
  [28] SFTRSTF — system reset from CPU reset flag Reset by software by writing the RMVF bit. Set by hardware when the system reset is due to CPU.The CPU can generate a system reset by writing SYSRESETREQ bit of AIRCR register of the core M33.
  [27] BORRSTF — BOR reset flag Reset by software by writing the RMVF bit. Set by hardware when a BOR reset occurs (pwr_bor_rst).
  [26] PINRSTF — pin reset flag (NRST) Reset by software by writing the RMVF bit. Set by hardware when a reset from pin occurs.
  [23] RMVF — remove reset flag Set and reset by software to reset the value of the reset flags.
